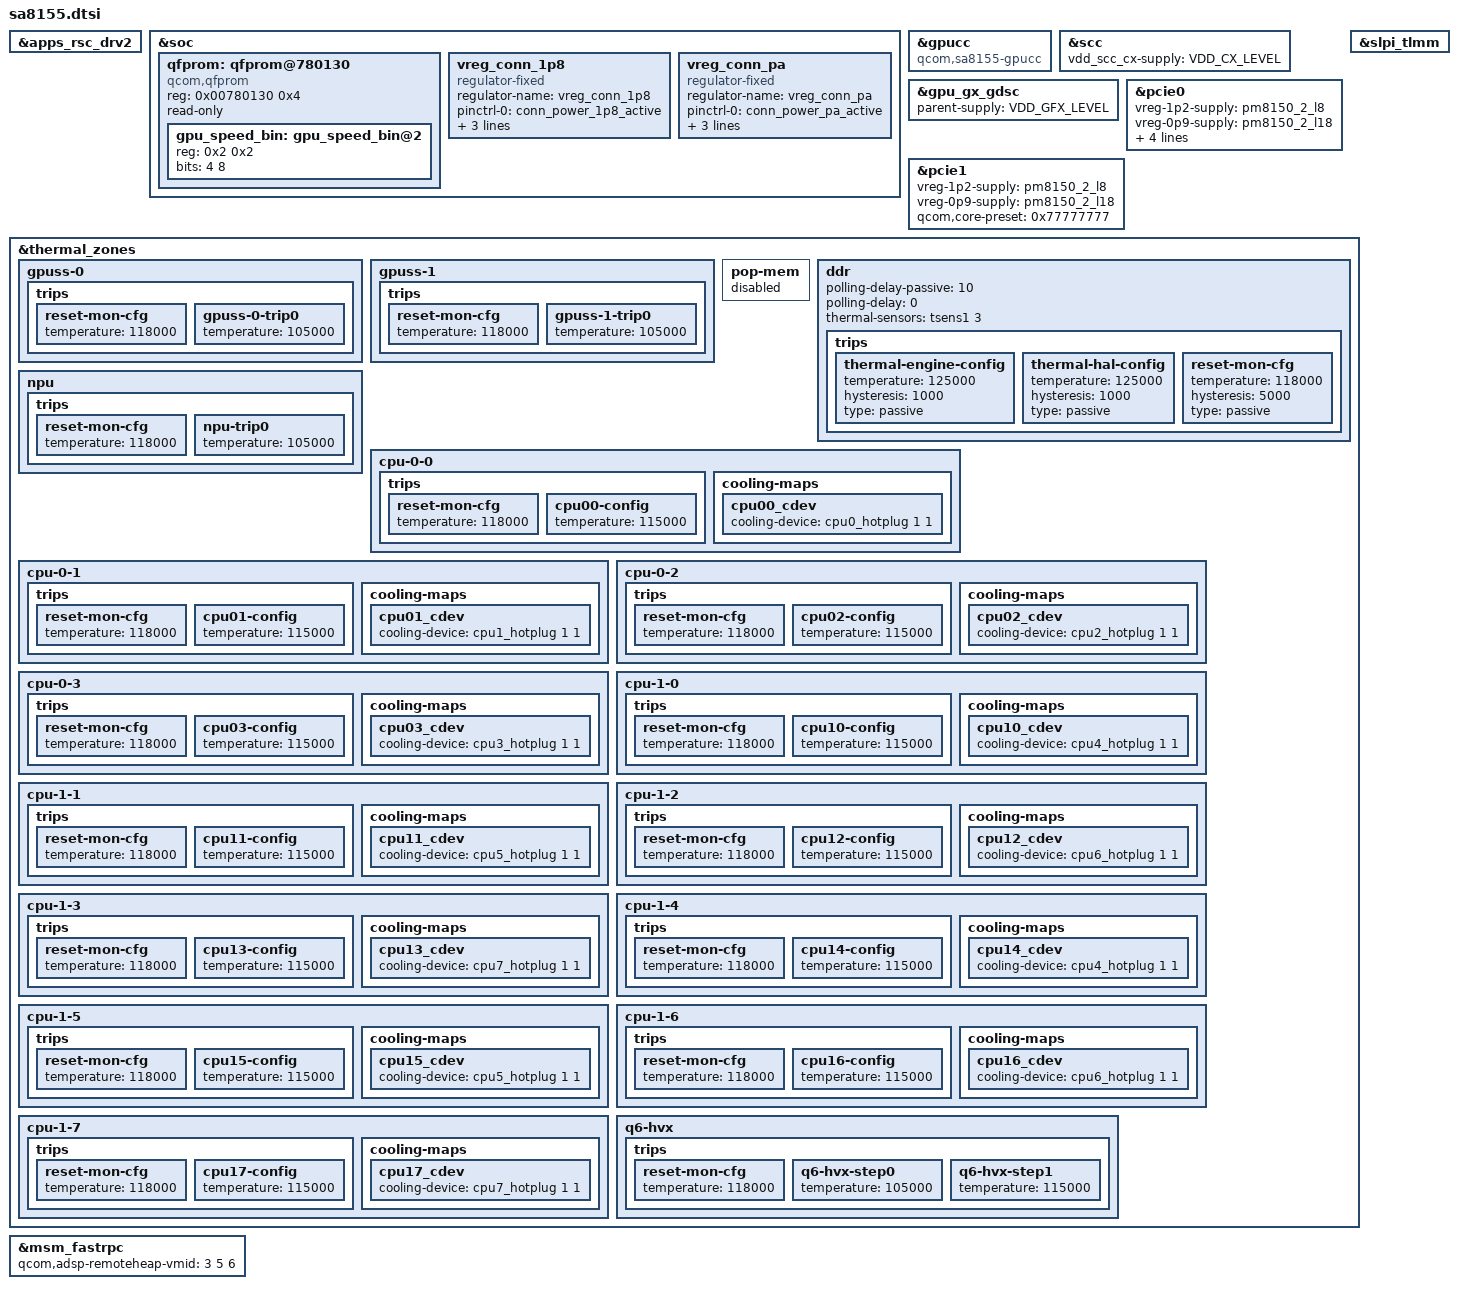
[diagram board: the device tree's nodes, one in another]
// SPDX-License-Identifier: BSD-3-Clause
/*
 * Copyright (c) 2024 Qualcomm Innovation Center, Inc. All rights reserved.
 */

#include <dt-bindings/gpio/gpio.h>

/* Remove regulator nodes specific to SM8150 */
&apps_rsc_drv2 {
	/delete-node/ regulator-pm8150-s4;
	/delete-node/ rpmh-regulator-msslvl;
	/delete-node/ rpmh-regulator-smpa2;
	/delete-node/ rpmh-regulator-ebilvl;
	/delete-node/ rpmh-regulator-smpa5;
	/delete-node/ rpmh-regulator-smpa6;
	/delete-node/ rpmh-regulator-ldoa1;
	/delete-node/ rpmh-regulator-ldoa2;
	/delete-node/ rpmh-regulator-ldoa3;
	/delete-node/ rpmh-regulator-lmxlvl;
	/delete-node/ rpmh-regulator-ldoa5;
	/delete-node/ rpmh-regulator-ldoa6;
	/delete-node/ rpmh-regulator-ldoa7;
	/delete-node/ rpmh-regulator-lcxlvl;
	/delete-node/ rpmh-regulator-ldoa9;
	/delete-node/ rpmh-regulator-ldoa10;
	/delete-node/ rpmh-regulator-ldoa11;
	/delete-node/ rpmh-regulator-ldoa12;
	/delete-node/ rpmh-regulator-ldoa13;
	/delete-node/ rpmh-regulator-ldoa14;
	/delete-node/ rpmh-regulator-ldoa15;
	/delete-node/ rpmh-regulator-ldoa16;
	/delete-node/ rpmh-regulator-ldoa17;
	/delete-node/ rpmh-regulator-smpc1;
	/delete-node/ rpmh-regulator-gfxlvl;
	/delete-node/ rpmh-regulator-mxlvl;
	/delete-node/ rpmh-regulator-mmcxlvl;
	/delete-node/ rpmh-regulator-cxlvl;
	/delete-node/ rpmh-regulator-smpc8;
	/delete-node/ rpmh-regulator-ldoc1;
	/delete-node/ rpmh-regulator-ldoc2;
	/delete-node/ rpmh-regulator-ldoc3;
	/delete-node/ rpmh-regulator-ldoc4;
	/delete-node/ rpmh-regulator-ldoc5;
	/delete-node/ rpmh-regulator-ldoc6;
	/delete-node/ rpmh-regulator-ldoc7;
	/delete-node/ rpmh-regulator-ldoc8;
	/delete-node/ rpmh-regulator-ldoc9;
	/delete-node/ rpmh-regulator-ldoc10;
	/delete-node/ rpmh-regulator-ldoc11;
	/delete-node/ rpmh-regulator-bobc1;
	/delete-node/ rpmh-regulator-smpf2;
	/delete-node/ rpmh-regulator-ldof2;
	/delete-node/ rpmh-regulator-ldof5;
	/delete-node/ rpmh-regulator-ldof6;
};

/* Add regulator nodes specific to SA8155 */
#include "sa8155-regulator.dtsi"

&soc {
	qfprom: qfprom@780130 {
		compatible = "qcom,qfprom";
		reg = <0x00780130 0x4>;
		#address-cells = <1>;
		#size-cells = <1>;
		read-only;
		ranges;
		gpu_speed_bin: gpu_speed_bin@2 {
			reg = <0x2 0x2>;
			bits = <4 8>;
			};
	};
};

/* Add CNSS power ctrl nodes specific to SA8155 */
&soc {
	/* PWR_CTR2_VDD_1P8 supply */
	vreg_conn_1p8: vreg_conn_1p8 {
		compatible = "regulator-fixed";
		regulator-name = "vreg_conn_1p8";
		pinctrl-names = "default";
		pinctrl-0 = <&conn_power_1p8_active>;
		startup-delay-us = <4000>;
		enable-active-high;
		gpio = <&tlmm 173 0>;
	};

	/* PWR_CTR1_VDD_PA supply */
	vreg_conn_pa: vreg_conn_pa {
		compatible = "regulator-fixed";
		regulator-name = "vreg_conn_pa";
		pinctrl-names = "default";
		pinctrl-0 = <&conn_power_pa_active>;
		startup-delay-us = <4000>;
		enable-active-high;
		gpio = <&tlmm 174 0>;
	};
};

&gpucc {
	compatible = "qcom,sa8155-gpucc", "syscon";
};

&scc {
	vdd_scc_cx-supply = <&VDD_CX_LEVEL>;
	status = "ok";
};

&gpu_gx_gdsc {
	parent-supply = <&VDD_GFX_LEVEL>;
};

&pcie0 {
	vreg-1p2-supply = <&pm8150_2_l8>;
	vreg-0p9-supply = <&pm8150_2_l18>;
	qcom,no-l1-supported;
	qcom,no-l1ss-supported;
	qcom,no-aux-clk-sync;
	qcom,core-preset = <0x77777777>;
};

&pcie1 {
	vreg-1p2-supply = <&pm8150_2_l8>;
	vreg-0p9-supply = <&pm8150_2_l18>;
	qcom,core-preset = <0x77777777>;
};

&slpi_tlmm {
	status = "ok";
};

&thermal_zones {
	/delete-node/ qcom,cpu-pause;

	gpuss-0 {
		trips {
			reset-mon-cfg {
				temperature = <118000>;
			};

			gpuss-0-trip0 {
				temperature = <105000>;
			};
		};
	};

	gpuss-1 {
		trips {
			reset-mon-cfg {
				temperature = <118000>;
			};

			gpuss-1-trip0 {
				temperature = <105000>;
			};
		};
	};

	pop-mem {
		status = "disabled";
	};

	ddr {
		polling-delay-passive = <10>;
		polling-delay = <0>;
		thermal-sensors = <&tsens1 3>;
		trips {
			thermal-engine-config {
				temperature = <125000>;
				hysteresis = <1000>;
				type = "passive";
			};

			thermal-hal-config {
				temperature = <125000>;
				hysteresis = <1000>;
				type = "passive";
			};

			reset-mon-cfg {
				temperature = <118000>;
				hysteresis = <5000>;
				type = "passive";
			};
		};
	};

	npu {
		trips {
			reset-mon-cfg {
				temperature = <118000>;
			};

			npu-trip0 {
				temperature = <105000>;
			};
		};
	};

	cpu-0-0 {
		trips {
			reset-mon-cfg {
				temperature = <118000>;
			};

			cpu00-config {
				temperature = <115000>;
			};
		};

		cooling-maps {
			cpu00_cdev {
				cooling-device = <&cpu0_hotplug 1 1>;
			};
		};
	};

	cpu-0-1 {
		trips {
			reset-mon-cfg {
				temperature = <118000>;
			};

			cpu01-config {
				temperature = <115000>;
			};
		};

		cooling-maps {
			cpu01_cdev {
				cooling-device = <&cpu1_hotplug 1 1>;
			};
		};
	};

	cpu-0-2 {
		trips {
			reset-mon-cfg {
				temperature = <118000>;
			};

			cpu02-config {
				temperature = <115000>;
			};
		};

		cooling-maps {
			cpu02_cdev {
				cooling-device = <&cpu2_hotplug 1 1>;
			};
		};
	};

	cpu-0-3 {
		trips {
			reset-mon-cfg {
				temperature = <118000>;
			};

			cpu03-config {
				temperature = <115000>;
			};
		};

		cooling-maps {
			cpu03_cdev {
				cooling-device = <&cpu3_hotplug 1 1>;
			};
		};
	};

	cpu-1-0 {
		trips {
			reset-mon-cfg {
				temperature = <118000>;
			};

			cpu10-config {
				temperature = <115000>;
			};
		};

		cooling-maps {
			cpu10_cdev {
				cooling-device = <&cpu4_hotplug 1 1>;
			};
		};
	};

	cpu-1-1 {
		trips {
			reset-mon-cfg {
				temperature = <118000>;
			};

			cpu11-config {
				temperature = <115000>;
			};
		};

		cooling-maps {
			cpu11_cdev {
				cooling-device = <&cpu5_hotplug 1 1>;
			};
		};
	};

	cpu-1-2 {
		trips {
			reset-mon-cfg {
				temperature = <118000>;
			};

			cpu12-config {
				temperature = <115000>;
			};
		};

		cooling-maps {
			cpu12_cdev {
				cooling-device = <&cpu6_hotplug 1 1>;
			};
		};
	};

	cpu-1-3 {
		trips {
			reset-mon-cfg {
				temperature = <118000>;
			};

			cpu13-config {
				temperature = <115000>;
			};
		};

		cooling-maps {
			cpu13_cdev {
				cooling-device = <&cpu7_hotplug 1 1>;
			};
		};
	};

	cpu-1-4 {
		trips {
			reset-mon-cfg {
				temperature = <118000>;
			};

			cpu14-config {
				temperature = <115000>;
			};
		};

		cooling-maps {
			cpu14_cdev {
				cooling-device = <&cpu4_hotplug 1 1>;
			};
		};
	};

	cpu-1-5 {
		trips {
			reset-mon-cfg {
				temperature = <118000>;
			};

			cpu15-config {
				temperature = <115000>;
			};
		};

		cooling-maps {
			cpu15_cdev {
				cooling-device = <&cpu5_hotplug 1 1>;
			};
		};
	};

	cpu-1-6 {
		trips {
			reset-mon-cfg {
				temperature = <118000>;
			};

			cpu16-config {
				temperature = <115000>;
			};
		};

		cooling-maps {
			cpu16_cdev {
				cooling-device = <&cpu6_hotplug 1 1>;
			};
		};
	};

	cpu-1-7 {
		trips {
			reset-mon-cfg {
				temperature = <118000>;
			};

			cpu17-config {
				temperature = <115000>;
			};
		};

		cooling-maps {
			cpu17_cdev {
				cooling-device = <&cpu7_hotplug 1 1>;
			};
		};
	};

	q6-hvx {
		trips {
			reset-mon-cfg {
				temperature = <118000>;
			};

			q6-hvx-step0 {
				temperature = <105000>;
			};

			q6-hvx-step1 {
				temperature = <115000>;
			};
		};
	};
};

&msm_fastrpc {
	qcom,adsp-remoteheap-vmid = <3 5 6>;
};
